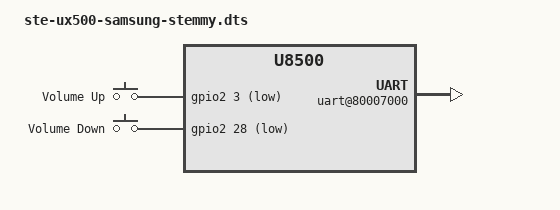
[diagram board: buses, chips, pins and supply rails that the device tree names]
// SPDX-License-Identifier: GPL-2.0-or-later
/dts-v1/;

#include "ste-dbx5x0-u-boot.dtsi"
#include "ste-ab8500.dtsi"
#include <dt-bindings/gpio/gpio.h>
#include <dt-bindings/input/input.h>

/ {
	compatible = "samsung,stemmy", "st-ericsson,u8500";

	chosen {
		stdout-path = &serial2;
	};

	soc {
		/* eMMC */
		sdi2_per3@80005000 {
			status = "okay";

			arm,primecell-periphid = <0x10480180>;
			max-frequency = <100000000>;
			bus-width = <8>;

			non-removable;
			cap-mmc-highspeed;
		};

		/* Debugging console UART */
		uart@80007000 {
			status = "okay";
		};

		mcde@a0350000 {
			status = "okay";
		};
	};

	gpio-keys {
		compatible = "gpio-keys";
		label = "GPIO Buttons";

		volume-up {
			label = "Volume Up";
			gpios = <&gpio2 3 GPIO_ACTIVE_LOW>;
			linux,code = <KEY_VOLUMEUP>;
		};

		volume-down {
			label = "Volume Down";
			gpios = <&gpio2 28 GPIO_ACTIVE_LOW>;
			linux,code = <KEY_VOLUMEDOWN>;
		};
	};
};
